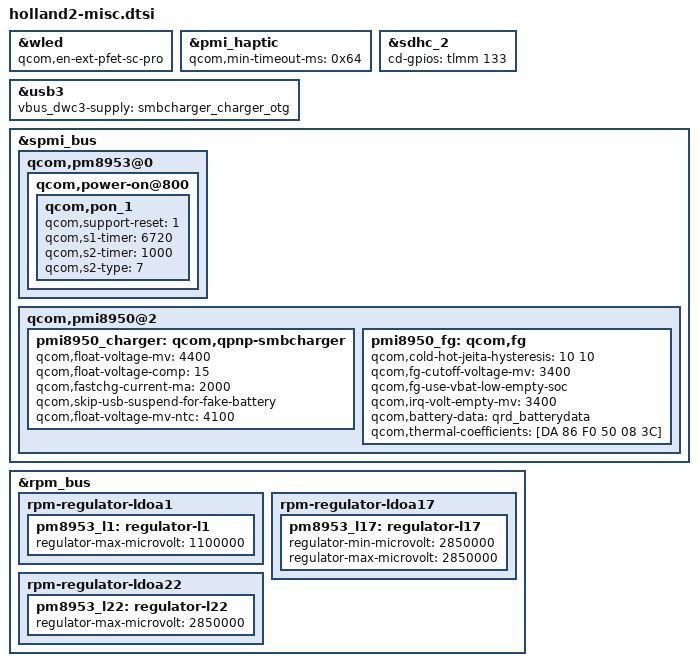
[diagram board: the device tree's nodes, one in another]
/* Copyright (c) 2020, The Linux Foundation. All rights reserved.
*  Copyright (c) 2020, Jebaitedneko.
*
* This program is free software; you can redistribute it and/or modify
* it under the terms of the GNU General Public License version 2 and
* only version 2 as published by the Free Software Foundation.
*
* This program is distributed in the hope that it will be useful,
* but WITHOUT ANY WARRANTY; without even the implied warranty of
* MERCHANTABILITY or FITNESS FOR A PARTICULAR PURPOSE.  See the
* GNU General Public License for more details.
*/

/delete-node/ &pm8953_typec;

&wled {
	qcom,en-ext-pfet-sc-pro;
};

&pmi_haptic {
	qcom,min-timeout-ms = <0x64>;
};

&sdhc_2 {
	cd-gpios = <&tlmm 133 0x0>;
};

&usb3 {
	vbus_dwc3-supply = <&smbcharger_charger_otg>;
};

&spmi_bus {

	qcom,pm8953@0 {

		qcom,power-on@800 {

			qcom,pon_1 {

				qcom,support-reset = <1>;
				qcom,s1-timer = <6720>;
				qcom,s2-timer = <1000>;
				qcom,s2-type = <7>;
			};
		};
	};

	qcom,pmi8950@2 {

		pmi8950_charger: qcom,qpnp-smbcharger {

			qcom,float-voltage-mv = <4400>;
			qcom,float-voltage-comp = <15>;
			qcom,fastchg-current-ma = <2000>;
			qcom,skip-usb-suspend-for-fake-battery;
			qcom,thermal-mitigation = <2000 2000 2000 2000 2000 2000 2000>;
			qcom,float-voltage-mv-ntc = <4100>;

			/delete-property/ qcom,external-typec;
			/delete-property/ qcom,fastchg-current-comp;
			/delete-property/ qcom,parallel-usb-min-current-ma;
			/delete-property/ qcom,parallel-usb-9v-min-current-ma;
			/delete-property/ qcom,parallel-allowed-lowering-ma;
			/delete-property/ qcom,typec-psy-name;
			/delete-property/ qcom,thermal-mitigation;

		};

		pmi8950_fg: qcom,fg {

			qcom,cold-bat-decidegc = <(-300)>;
			qcom,cool-bat-decidegc = <(-200)>;
			qcom,hot-bat-decidegc = <650>;
			qcom,warm-bat-decidegc = <610>;
			qcom,cold-hot-jeita-hysteresis = <10 10>;
			qcom,fg-cutoff-voltage-mv = <3400>;
			qcom,fg-use-vbat-low-empty-soc;
            		qcom,irq-volt-empty-mv = <3400>;
			qcom,battery-data = <&qrd_batterydata>;
			qcom,thermal-coefficients = [DA 86 F0 50 08 3C];

			/delete-property/ qcom,cold-bat-decidegc;
			/delete-property/ qcom,cool-bat-decidegc;
			/delete-property/ qcom,fg-therm-delay-us;
			/delete-property/ qcom,hot-bat-decidegc;
			/delete-property/ qcom,warm-bat-decidegc;

		};
	};
};

&rpm_bus {

	rpm-regulator-ldoa1 {
		pm8953_l1: regulator-l1 {
			regulator-max-microvolt = <1100000>;
		};
	};

	rpm-regulator-ldoa17 {

		pm8953_l17: regulator-l17 {
			regulator-min-microvolt = <2850000>;
			regulator-max-microvolt = <2850000>;
		};
	};
	
	rpm-regulator-ldoa22 {
		pm8953_l22: regulator-l22 {
			regulator-max-microvolt = <2850000>;
		};
	};
};
